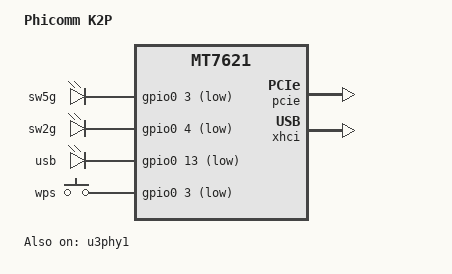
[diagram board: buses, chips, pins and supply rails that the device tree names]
/dts-v1/;

/dts-v1/;

#include "mt7621.dtsi"
#include <dt-bindings/input/input.h>
#include "mt7621-spi-16m-layout.dtsi"
#include "mt7621-raeth-gmac2.dtsi"
#include "mt7621-pinctrl-default-gpio.dtsi"

/ {
	compatible = "mediatek,mt7621-soc";
	model = "Phicomm K2P";

	chosen {
		bootargs = "console=ttyS0,57600";
	};

	leds {
		compatible = "gpio-leds";
    
		wlan5g {
			label = "sw5g";
			gpios = <&gpio0 3 GPIO_ACTIVE_LOW>;
			linux,default-trigger = "phy1radio";
		};

		wlan2g {
			label = "sw2g";
			gpios = <&gpio0 4 GPIO_ACTIVE_LOW>;
			linux,default-trigger = "phy0radio";
		};

		usb {
			label = "usb";
			gpios = <&gpio0 13 GPIO_ACTIVE_LOW>;
			linux,default-trigger = "usbport";
		};
	};
	
	gpio-keys-polled {
		compatible = "gpio-keys-polled";
		#address-cells = <1>;
		#size-cells = <0>;
		poll-interval = <20>;

		wps {
			label = "wps";
			gpios = <&gpio0 3 GPIO_ACTIVE_LOW>;
			linux,code = <KEY_WPS_BUTTON>;
		};
	};
};

&pcie {
	status = "okay";
};

&xhci {
	status = "okay";
};

&u3phy1 {
	status = "okay";
};
